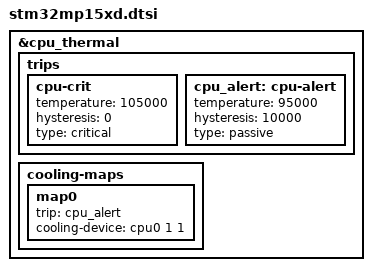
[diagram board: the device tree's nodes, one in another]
// SPDX-License-Identifier: (GPL-2.0-or-later OR BSD-3-Clause)
/*
 * Copyright (C) STMicroelectronics 2022 - All Rights Reserved
 * Author: Alexandre Torgue <alexandre.torgue@foss.st.com> for STMicroelectronics.
 */

&cpu_thermal {
	trips {
		cpu-crit {
			temperature = <105000>;
			hysteresis = <0>;
			type = "critical";
		};

		cpu_alert: cpu-alert {
			temperature = <95000>;
			hysteresis = <10000>;
			type = "passive";
		};
	};

	cooling-maps {
		map0 {
			trip = <&cpu_alert>;
			cooling-device = <&cpu0 1 1>;
		};
	};
};
